# K1921VG015 register map
Vendor: NIIET; Series: K1921Vxxx; File version: 1.14
Registers are 32-bit, read-write, reset 0x0 unless marked. A register's access mark holds for its fields unless they carry their own. Offsets are from the block's base; [hi:lo] are bit positions; lines under a group give offsets from that group; {n}, {i} and the like mark numbered series; 'fields as' and 'values as' point back to an identical list.

## TSENS — Temperature sensor controller registers
Base 0x30011000
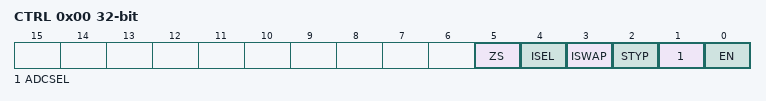
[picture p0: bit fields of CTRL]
0x00 CTRL — TSENS control register
  [5] ZS — Zero sample for calibration
  [4] ISEL — Current source
  [3] ISWAP
  [2] STYP — Sense type select
  [1] ADCSEL — ADC select
  [0] EN — Enable temperatire sensor

## ADCSD — ADC SAR control registers
Base 0x30012000
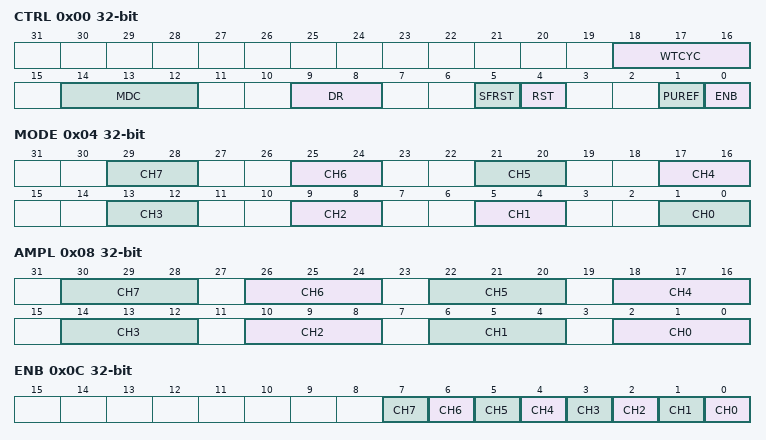
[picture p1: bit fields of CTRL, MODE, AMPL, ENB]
0x00 CTRL — Enable sequencer register
  [18:16] WTCYC — reserved
  [14:12] MDC — reserved
  [9:8] DR — reserved
  [5] SFRST — reserved
  [4] RST — reserved
  [1] PUREF — reserved
  [0] ENB — reserved
0x04 MODE — Sequencer sync register
  [4n+1:4n] CH{n} (n=2..7) — reserved
  [5:4] CH1 — Inverce input data on Chanel4
  [1:0] CH0 — Inverce input data on Chanel0
0x08 AMPL — Chanel amplifier register
  [4n+2:4n] CH{n} (n=0..7) — Amplifying for Chanel{n}
0x0C ENB — Enable conversion register
  [n] CH{n} (n=0..7) — Enable conversion on Chanel{n}
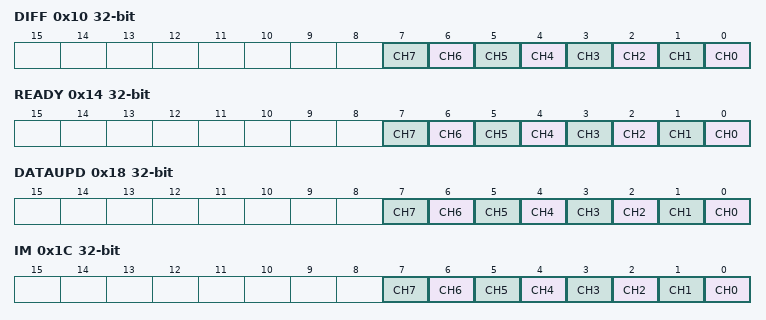
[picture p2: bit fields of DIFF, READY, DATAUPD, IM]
0x10 DIFF — Enable differencial mode for channels
  [n] CH{n} (n=0..7) — Enable conversion on Chanel{n}
0x14 READY ro — Ready for conversion result register
  [n] CH{n} (n=0..7) — Status of Chanel {n}
0x18 DATAUPD — Flag of successful conversion
  [n] CH{n} (n=0..7)
0x1C IM — Interrupt mask
  [n] CH{n} (n=0..7)
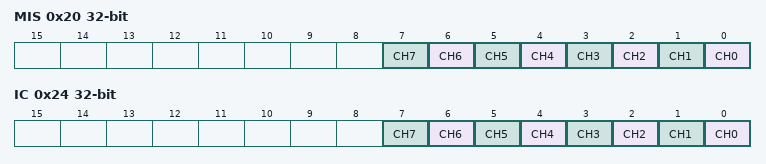
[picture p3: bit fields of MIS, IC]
0x20 MIS ro — Masked Interrupt Status
  [n] CH{n} (n=0..7)
0x24 IC wo — Interrupt Status Clear
  [n] CH{n} (n=0..7)
{0x40+4i} DATA[{i}] (i=0..7) group
  0x00 DATA ro — ADC Conversion data
    [15:0] DATA

## DMA — DMA control registers
Base 0x3000C000
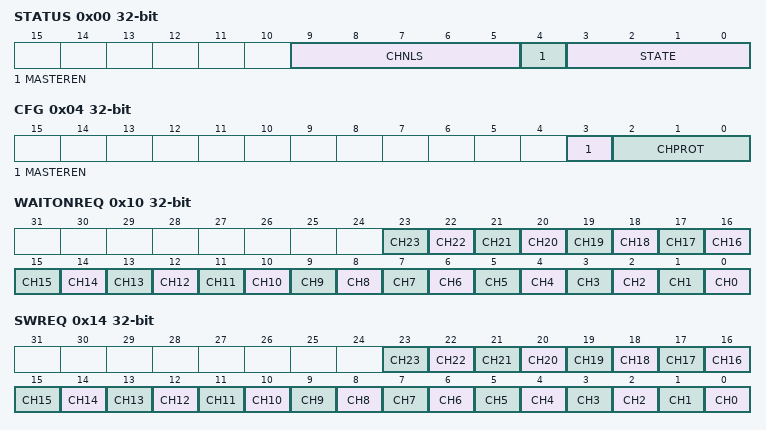
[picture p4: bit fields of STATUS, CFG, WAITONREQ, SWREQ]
0x00 STATUS ro — Status DMA register
  [9:5] CHNLS — Number channel DMA (write: N-1)
    on read: 0=Free (At rest); 1=ReadConfigData (Reading the config data structure); 2=ReadSrcDataEndPtr (Reading sourse data end pointer); 3=ReadDstDataEndPtr (Reading destination data end pointer); 4=ReadSrcData (Reading source data); 5=WrireDstData (Writing data to the destination); 6=WaitReq (Waiting for a request); 7=WriteConfigData (Write config structure of the channel); 8=Pause (Suspended); 9=Done (Executed); 10=PeriphScatGath (mode "peripheral scather-gather")
  [4] MASTEREN — Indicate enable DMA
    values as CHNLS
  [3:0] STATE — State of DMA
0x04 CFG — DMA configuration register
  [3] MASTEREN — Enable DMA
  [2:0] CHPROT — Sets the AHB-Lite protection
0x08 BASEPTR — Channel control data base pointer
  [31:0] VAL
0x0C ALTBASEPTR ro — Channel alternate control data base pointer
  [31:0] VAL
0x10 WAITONREQ ro — Channel wait on request status
  [n] CH{n} (n=0..23) — Returns the status of the DMA request signals
0x14 SWREQ wo — Channel software request
  [n] CH{n} (n=0..23) — Set software request on channel
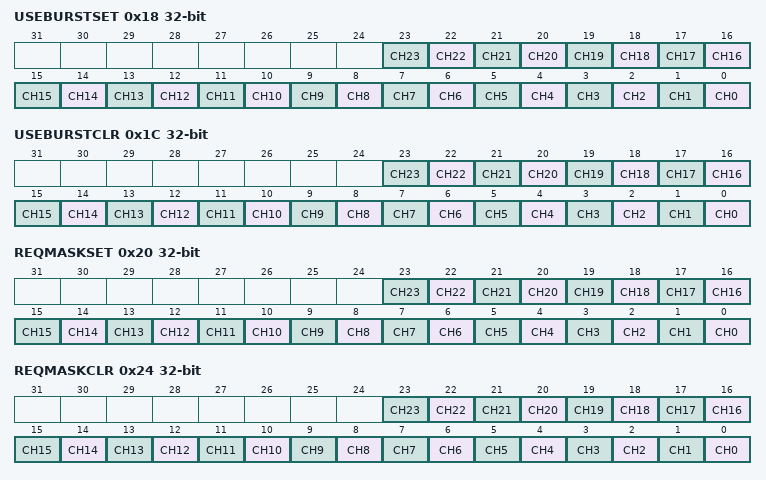
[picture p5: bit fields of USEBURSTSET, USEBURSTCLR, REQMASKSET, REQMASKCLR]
0x18 USEBURSTSET — Channel useburst set
  [n] CH{n} (n=0..23) — Enable single requests
0x1C USEBURSTCLR wo — Channel useburst clear
  [n] CH{n} (n=0..23) — Disable single requests
0x20 REQMASKSET — Channel request mask set
  [n] CH{n} (n=0..23) — External requests are enabled for channel
0x24 REQMASKCLR wo — Channel request mask clear
  [n] CH{n} (n=0..23) — External requests are disabled for channel
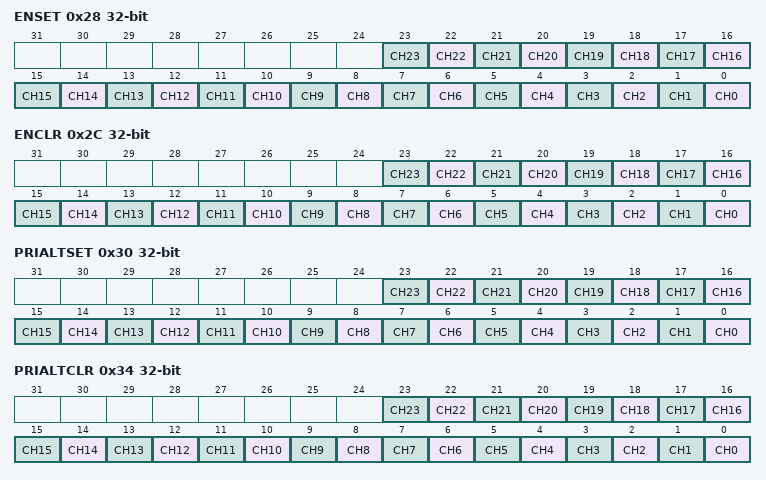
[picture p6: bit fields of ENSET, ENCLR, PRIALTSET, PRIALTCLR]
0x28 ENSET — Channel enable set
  [n] CH{n} (n=0..23) — Enable channel
0x2C ENCLR wo — Channel enable clear
  [n] CH{n} (n=0..23) — Disable channel
0x30 PRIALTSET — Channel primary-alternate set
  [n] CH{n} (n=0..23) — Set primary / alternate channel control data structure
0x34 PRIALTCLR wo — Channel primary-alternate clear
  [n] CH{n} (n=0..23) — Clear primary / alternate channel control data structure
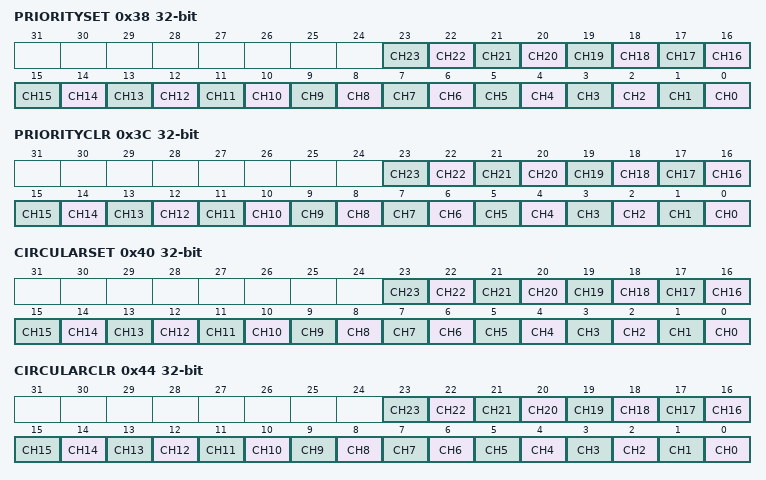
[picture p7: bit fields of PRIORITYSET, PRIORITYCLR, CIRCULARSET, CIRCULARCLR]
0x38 PRIORITYSET — Channel priority set
  [n] CH{n} (n=0..23) — Set the priority of channel
0x3C PRIORITYCLR wo — Channel priority clear
  [n] CH{n} (n=0..23) — Clear the priority
0x40 CIRCULARSET — Channel circular set
  [n] CH{n} (n=0..23) — Set the channel circular mode
0x44 CIRCULARCLR wo — Channel circular clear
  [n] CH{n} (n=0..23) — Clear the channel circular mode
0x4C ERRCLR — Bus error register
  [0] VAL — Indicate Error on bus AHB-Lite
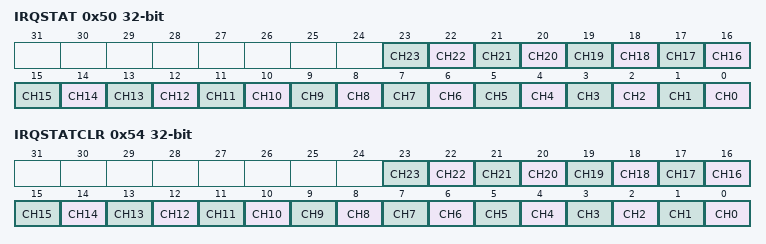
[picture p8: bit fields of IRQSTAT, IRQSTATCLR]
0x50 IRQSTAT ro — IRQ Status register
  [n] CH{n} (n=0..23)
0x54 IRQSTATCLR wo — IRQ Clear Status register
  [n] CH{n} (n=0..23)
